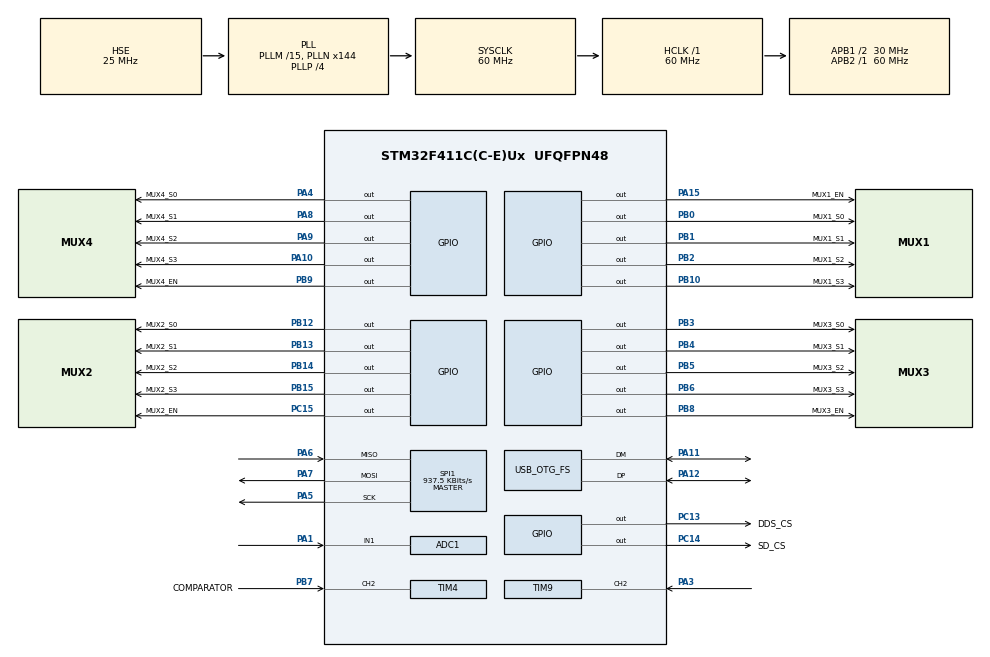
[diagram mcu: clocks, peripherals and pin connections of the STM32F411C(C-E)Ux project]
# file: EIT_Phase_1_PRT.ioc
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ADC1.Channel-2\#ChannelRegularConversion=ADC_CHANNEL_1
ADC1.ContinuousConvMode=DISABLE
ADC1.DMAContinuousRequests=ENABLE
ADC1.ExternalTrigConv=ADC_EXTERNALTRIGCONV_T2_TRGO
ADC1.NbrOfConversion=1
ADC1.NbrOfConversionFlag=1
ADC1.Rank-2\#ChannelRegularConversion=1
ADC1.SamplingTime-2\#ChannelRegularConversion=ADC_SAMPLETIME_15CYCLES
ADC1.master=1
Dma.ADC1.0.Direction=DMA_PERIPH_TO_MEMORY
Dma.ADC1.0.FIFOMode=DMA_FIFOMODE_DISABLE
Dma.ADC1.0.Instance=DMA2_Stream0
Dma.ADC1.0.MemDataAlignment=DMA_MDATAALIGN_HALFWORD
Dma.ADC1.0.MemInc=DMA_MINC_ENABLE
Dma.ADC1.0.Mode=DMA_CIRCULAR
Dma.ADC1.0.PeriphDataAlignment=DMA_PDATAALIGN_HALFWORD
Dma.ADC1.0.PeriphInc=DMA_PINC_DISABLE
Dma.ADC1.0.Priority=DMA_PRIORITY_LOW
Dma.Request0=ADC1
Mcu.Family=STM32F4
Mcu.Name=STM32F411C(C-E)Ux
Mcu.Package=UFQFPN48
NVIC.DMA2_Stream0_IRQn=true\:0\:0\:false\:false\:true\:false\:true\:true
NVIC.OTG_FS_IRQn=true\:0\:0\:false\:false\:true\:false\:true\:true
NVIC.PriorityGroup=NVIC_PRIORITYGROUP_4
NVIC.TIM4_IRQn=true\:0\:0\:false\:false\:true\:true\:true\:true
PA1.Signal=ADCx_IN1
PA10.GPIO_Label=MUX4_S3
PA10.Signal=GPIO_Output
PA11.Mode=Device_Only
PA11.Signal=USB_OTG_FS_DM
PA12.Mode=Device_Only
PA12.Signal=USB_OTG_FS_DP
PA13.Mode=Serial_Wire
PA13.Signal=SYS_JTMS-SWDIO
PA14.Mode=Serial_Wire
PA14.Signal=SYS_JTCK-SWCLK
PA15.GPIO_Label=MUX1_EN
PA15.Signal=GPIO_Output
PA3.Signal=S_TIM9_CH2
PA4.GPIO_Label=MUX4_S0
PA4.Signal=GPIO_Output
PA5.Mode=Full_Duplex_Master
PA5.Signal=SPI1_SCK
PA6.Mode=Full_Duplex_Master
PA6.Signal=SPI1_MISO
PA7.Mode=Full_Duplex_Master
PA7.Signal=SPI1_MOSI
PA8.GPIO_Label=MUX4_S1
PA8.Signal=GPIO_Output
PA9.GPIO_Label=MUX4_S2
PA9.Signal=GPIO_Output
PB0.GPIO_Label=MUX1_S0
PB0.Signal=GPIO_Output
PB1.GPIO_Label=MUX1_S1
PB1.Signal=GPIO_Output
PB10.GPIO_Label=MUX1_S3
PB10.Signal=GPIO_Output
PB12.GPIO_Label=MUX2_S0
PB12.Signal=GPIO_Output
PB13.GPIO_Label=MUX2_S1
PB13.Signal=GPIO_Output
PB14.GPIO_Label=MUX2_S2
PB14.Signal=GPIO_Output
PB15.GPIO_Label=MUX2_S3
PB15.Signal=GPIO_Output
PB2.GPIO_Label=MUX1_S2
PB2.Signal=GPIO_Output
PB3.GPIO_Label=MUX3_S0
PB3.Signal=GPIO_Output
PB4.GPIO_Label=MUX3_S1
PB4.Signal=GPIO_Output
PB5.GPIO_Label=MUX3_S2
PB5.Signal=GPIO_Output
PB6.GPIO_Label=MUX3_S3
PB6.Signal=GPIO_Output
PB7.GPIO_Label=COMPARATOR
PB7.GPIO_PuPd=GPIO_PULLDOWN
PB7.Signal=S_TIM4_CH2
PB8.GPIO_Label=MUX3_EN
PB8.Signal=GPIO_Output
PB9.GPIO_Label=MUX4_EN
PB9.Signal=GPIO_Output
PC13-ANTI_TAMP.GPIO_Label=DDS_CS
PC13-ANTI_TAMP.Signal=GPIO_Output
PC14-OSC32_IN.GPIO_Label=SD_CS
PC14-OSC32_IN.Signal=GPIO_Output
PC15-OSC32_OUT.GPIO_Label=MUX2_EN
PC15-OSC32_OUT.Signal=GPIO_Output
PH0\ -\ OSC_IN.Mode=HSE-External-Oscillator
PH0\ -\ OSC_IN.Signal=RCC_OSC_IN
PH1\ -\ OSC_OUT.Mode=HSE-External-Oscillator
PH1\ -\ OSC_OUT.Signal=RCC_OSC_OUT
ProjectManager.HeapSize=0x200
ProjectManager.StackSize=0x400
ProjectManager.TargetToolchain=STM32CubeIDE
RCC.48MHZClocksFreq_Value=48000000
RCC.AHBFreq_Value=60000000
RCC.APB1CLKDivider=RCC_HCLK_DIV2
RCC.APB1Freq_Value=30000000
RCC.APB1TimFreq_Value=60000000
RCC.APB2Freq_Value=60000000
RCC.APB2TimFreq_Value=60000000
RCC.CortexFreq_Value=60000000
RCC.HCLKFreq_Value=60000000
RCC.HSE_VALUE=25000000
RCC.HSI_VALUE=16000000
RCC.LSE_VALUE=32768
RCC.PLLM=15
RCC.PLLN=144
RCC.PLLP=RCC_PLLP_DIV4
RCC.PLLQ=5
RCC.SYSCLKFreq_VALUE=60000000
RCC.SYSCLKSource=RCC_SYSCLKSOURCE_PLLCLK
RCC.VCOOutputFreq_Value=240000000
SH.ADCx_IN1.0=ADC1_IN1,IN1
SH.S_TIM4_CH2.0=TIM4_CH2,Input_Capture2_from_TI2
SH.S_TIM9_CH2.0=TIM9_CH2,Input_Capture2_from_TI2
SPI1.BaudRatePrescaler=SPI_BAUDRATEPRESCALER_64
SPI1.CLKPolarity=SPI_POLARITY_HIGH
SPI1.CalculateBaudRate=937.5 KBits/s
SPI1.Direction=SPI_DIRECTION_2LINES
SPI1.Mode=SPI_MODE_MASTER
SPI1.VirtualType=VM_MASTER
TIM2.AutoReloadPreload=TIM_AUTORELOAD_PRELOAD_ENABLE
TIM2.Period=74
TIM2.TIM_MasterOutputTrigger=TIM_TRGO_UPDATE
TIM4.AutoReloadPreload=TIM_AUTORELOAD_PRELOAD_ENABLE
TIM4.Channel-Input_Capture2_from_TI2=TIM_CHANNEL_2
TIM4.ICFilter_CH2=1
TIM9.Channel-Input_Capture2_from_TI2=TIM_CHANNEL_2
USB_DEVICE.CLASS_NAME_FS=CDC
USB_DEVICE.VirtualMode=Cdc
USB_DEVICE.VirtualModeFS=Cdc_FS
USB_OTG_FS.VirtualMode=Device_Only
VP_TIM2_VS_ClockSourceINT.Mode=Internal
VP_TIM4_VS_ClockSourceINT.Mode=Internal
VP_USB_DEVICE_VS_USB_DEVICE_CDC_FS.Mode=CDC_FS
board=custom

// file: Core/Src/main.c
/* USER CODE BEGIN Header */
/**
  ******************************************************************************
  * @file           : main.c
  * @brief          : Main program body
  ******************************************************************************
  * @attention
  *
  * Copyright (c) 2026 STMicroelectronics.
  * All rights reserved.
  *
  * This software is licensed under terms that can be found in the LICENSE file
  * in the root directory of this software component.
  * If no LICENSE file comes with this software, it is provided AS-IS.
  *
  ******************************************************************************
  */
/* USER CODE END Header */
#include "main.h"
#include "usb_device.h"

/* USER CODE BEGIN Includes */
#include "app.hpp"
/* USER CODE END Includes */

ADC_HandleTypeDef hadc1;
DMA_HandleTypeDef hdma_adc1;

SPI_HandleTypeDef hspi1;

TIM_HandleTypeDef htim2;
TIM_HandleTypeDef htim4;
TIM_HandleTypeDef htim9;

void SystemClock_Config(void);
static void MX_GPIO_Init(void);
static void MX_DMA_Init(void);
static void MX_SPI1_Init(void);
static void MX_ADC1_Init(void);
static void MX_TIM2_Init(void);
static void MX_TIM4_Init(void);
static void MX_TIM9_Init(void);

int main(void)
{

  /* MCU Configuration--------------------------------------------------------*/

  /* Reset of all peripherals, Initializes the Flash interface and the Systick. */
  HAL_Init();

  /* Configure the system clock */
  SystemClock_Config();

  /* Initialize all configured peripherals */
  MX_GPIO_Init();
  MX_DMA_Init();
  MX_SPI1_Init();
  MX_USB_DEVICE_Init();
  MX_ADC1_Init();
  MX_TIM2_Init();
  MX_TIM4_Init();
  MX_TIM9_Init();
  /* USER CODE BEGIN 2 */
  app_setup();
  /* USER CODE END 2 */

  /* Infinite loop */
  /* USER CODE BEGIN WHILE */
  while (1)
  {
	  app_loop();
    /* USER CODE END WHILE */

  }
}

void SystemClock_Config(void)
{
  RCC_OscInitTypeDef RCC_OscInitStruct = {0};
  RCC_ClkInitTypeDef RCC_ClkInitStruct = {0};

  /** Configure the main internal regulator output voltage
  */
  __HAL_RCC_PWR_CLK_ENABLE();
  __HAL_PWR_VOLTAGESCALING_CONFIG(PWR_REGULATOR_VOLTAGE_SCALE1);

  /** Initializes the RCC Oscillators according to the specified parameters
  * in the RCC_OscInitTypeDef structure.
  */
  RCC_OscInitStruct.OscillatorType = RCC_OSCILLATORTYPE_HSE;
  RCC_OscInitStruct.HSEState = RCC_HSE_ON;
  RCC_OscInitStruct.PLL.PLLState = RCC_PLL_ON;
  RCC_OscInitStruct.PLL.PLLSource = RCC_PLLSOURCE_HSE;
  RCC_OscInitStruct.PLL.PLLM = 15;
  RCC_OscInitStruct.PLL.PLLN = 144;
  RCC_OscInitStruct.PLL.PLLP = RCC_PLLP_DIV4;
  RCC_OscInitStruct.PLL.PLLQ = 5;
  if (HAL_RCC_OscConfig(&RCC_OscInitStruct) != HAL_OK)
  {
    Error_Handler();
  }

  /** Initializes the CPU, AHB and APB buses clocks
  */
  RCC_ClkInitStruct.ClockType = RCC_CLOCKTYPE_HCLK|RCC_CLOCKTYPE_SYSCLK
                              |RCC_CLOCKTYPE_PCLK1|RCC_CLOCKTYPE_PCLK2;
  RCC_ClkInitStruct.SYSCLKSource = RCC_SYSCLKSOURCE_PLLCLK;
  RCC_ClkInitStruct.AHBCLKDivider = RCC_SYSCLK_DIV1;
  RCC_ClkInitStruct.APB1CLKDivider = RCC_HCLK_DIV2;
  RCC_ClkInitStruct.APB2CLKDivider = RCC_HCLK_DIV1;

  if (HAL_RCC_ClockConfig(&RCC_ClkInitStruct, FLASH_LATENCY_1) != HAL_OK)
  {
    Error_Handler();
  }
}

static void MX_ADC1_Init(void)
{

  ADC_ChannelConfTypeDef sConfig = {0};

  /** Configure the global features of the ADC (Clock, Resolution, Data Alignment and number of conversion)
  */
  hadc1.Instance = ADC1;
  hadc1.Init.ClockPrescaler = ADC_CLOCK_SYNC_PCLK_DIV2;
  hadc1.Init.Resolution = ADC_RESOLUTION_12B;
  hadc1.Init.ScanConvMode = DISABLE;
  hadc1.Init.ContinuousConvMode = DISABLE;
  hadc1.Init.DiscontinuousConvMode = DISABLE;
  hadc1.Init.ExternalTrigConvEdge = ADC_EXTERNALTRIGCONVEDGE_RISING;
  hadc1.Init.ExternalTrigConv = ADC_EXTERNALTRIGCONV_T2_TRGO;
  hadc1.Init.DataAlign = ADC_DATAALIGN_RIGHT;
  hadc1.Init.NbrOfConversion = 1;
  hadc1.Init.DMAContinuousRequests = ENABLE;
  hadc1.Init.EOCSelection = ADC_EOC_SINGLE_CONV;
  if (HAL_ADC_Init(&hadc1) != HAL_OK)
  {
    Error_Handler();
  }

  /** Configure for the selected ADC regular channel its corresponding rank in the sequencer and its sample time.
  */
  sConfig.Channel = ADC_CHANNEL_1;
  sConfig.Rank = 1;
  sConfig.SamplingTime = ADC_SAMPLETIME_15CYCLES;
  if (HAL_ADC_ConfigChannel(&hadc1, &sConfig) != HAL_OK)
  {
    Error_Handler();
  }

}

static void MX_SPI1_Init(void)
{

  /* SPI1 parameter configuration*/
  hspi1.Instance = SPI1;
  hspi1.Init.Mode = SPI_MODE_MASTER;
  hspi1.Init.Direction = SPI_DIRECTION_2LINES;
  hspi1.Init.DataSize = SPI_DATASIZE_8BIT;
  hspi1.Init.CLKPolarity = SPI_POLARITY_HIGH;
  hspi1.Init.CLKPhase = SPI_PHASE_1EDGE;
  hspi1.Init.NSS = SPI_NSS_SOFT;
  hspi1.Init.BaudRatePrescaler = SPI_BAUDRATEPRESCALER_64;
  hspi1.Init.FirstBit = SPI_FIRSTBIT_MSB;
  hspi1.Init.TIMode = SPI_TIMODE_DISABLE;
  hspi1.Init.CRCCalculation = SPI_CRCCALCULATION_DISABLE;
  hspi1.Init.CRCPolynomial = 10;
  if (HAL_SPI_Init(&hspi1) != HAL_OK)
  {
    Error_Handler();
  }

}

static void MX_TIM2_Init(void)
{

  TIM_ClockConfigTypeDef sClockSourceConfig = {0};
  TIM_MasterConfigTypeDef sMasterConfig = {0};

  htim2.Instance = TIM2;
  htim2.Init.Prescaler = 0;
  htim2.Init.CounterMode = TIM_COUNTERMODE_UP;
  htim2.Init.Period = 74;
  htim2.Init.ClockDivision = TIM_CLOCKDIVISION_DIV1;
  htim2.Init.AutoReloadPreload = TIM_AUTORELOAD_PRELOAD_ENABLE;
  if (HAL_TIM_Base_Init(&htim2) != HAL_OK)
  {
    Error_Handler();
  }
  sClockSourceConfig.ClockSource = TIM_CLOCKSOURCE_INTERNAL;
  if (HAL_TIM_ConfigClockSource(&htim2, &sClockSourceConfig) != HAL_OK)
  {
    Error_Handler();
  }
  sMasterConfig.MasterOutputTrigger = TIM_TRGO_UPDATE;
  sMasterConfig.MasterSlaveMode = TIM_MASTERSLAVEMODE_DISABLE;
  if (HAL_TIMEx_MasterConfigSynchronization(&htim2, &sMasterConfig) != HAL_OK)
  {
    Error_Handler();
  }

}

static void MX_TIM4_Init(void)
{

  TIM_ClockConfigTypeDef sClockSourceConfig = {0};
  TIM_MasterConfigTypeDef sMasterConfig = {0};
  TIM_IC_InitTypeDef sConfigIC = {0};

  htim4.Instance = TIM4;
  htim4.Init.Prescaler = 0;
  htim4.Init.CounterMode = TIM_COUNTERMODE_UP;
  htim4.Init.Period = 65535;
  htim4.Init.ClockDivision = TIM_CLOCKDIVISION_DIV1;
  htim4.Init.AutoReloadPreload = TIM_AUTORELOAD_PRELOAD_ENABLE;
  if (HAL_TIM_Base_Init(&htim4) != HAL_OK)
  {
    Error_Handler();
  }
  sClockSourceConfig.ClockSource = TIM_CLOCKSOURCE_INTERNAL;
  if (HAL_TIM_ConfigClockSource(&htim4, &sClockSourceConfig) != HAL_OK)
  {
    Error_Handler();
  }
  if (HAL_TIM_IC_Init(&htim4) != HAL_OK)
  {
    Error_Handler();
  }
  sMasterConfig.MasterOutputTrigger = TIM_TRGO_RESET;
  sMasterConfig.MasterSlaveMode = TIM_MASTERSLAVEMODE_DISABLE;
  if (HAL_TIMEx_MasterConfigSynchronization(&htim4, &sMasterConfig) != HAL_OK)
  {
    Error_Handler();
  }
  sConfigIC.ICPolarity = TIM_INPUTCHANNELPOLARITY_RISING;
  sConfigIC.ICSelection = TIM_ICSELECTION_DIRECTTI;
  sConfigIC.ICPrescaler = TIM_ICPSC_DIV1;
  sConfigIC.ICFilter = 1;
  if (HAL_TIM_IC_ConfigChannel(&htim4, &sConfigIC, TIM_CHANNEL_2) != HAL_OK)
  {
    Error_Handler();
  }

}

static void MX_TIM9_Init(void)
{

  TIM_IC_InitTypeDef sConfigIC = {0};

  htim9.Instance = TIM9;
  htim9.Init.Prescaler = 0;
  htim9.Init.CounterMode = TIM_COUNTERMODE_UP;
  htim9.Init.Period = 65535;
  htim9.Init.ClockDivision = TIM_CLOCKDIVISION_DIV1;
  htim9.Init.AutoReloadPreload = TIM_AUTORELOAD_PRELOAD_DISABLE;
  if (HAL_TIM_IC_Init(&htim9) != HAL_OK)
  {
    Error_Handler();
  }
  sConfigIC.ICPolarity = TIM_INPUTCHANNELPOLARITY_RISING;
  sConfigIC.ICSelection = TIM_ICSELECTION_DIRECTTI;
  sConfigIC.ICPrescaler = TIM_ICPSC_DIV1;
  sConfigIC.ICFilter = 0;
  if (HAL_TIM_IC_ConfigChannel(&htim9, &sConfigIC, TIM_CHANNEL_2) != HAL_OK)
  {
    Error_Handler();
  }

}

static void MX_DMA_Init(void)
{

  /* DMA controller clock enable */
  __HAL_RCC_DMA2_CLK_ENABLE();

  /* DMA interrupt init */
  /* DMA2_Stream0_IRQn interrupt configuration */
  HAL_NVIC_SetPriority(DMA2_Stream0_IRQn, 0, 0);
  HAL_NVIC_EnableIRQ(DMA2_Stream0_IRQn);

}

static void MX_GPIO_Init(void)
{
  GPIO_InitTypeDef GPIO_InitStruct = {0};

  /* GPIO Ports Clock Enable */
  __HAL_RCC_GPIOC_CLK_ENABLE();
  __HAL_RCC_GPIOH_CLK_ENABLE();
  __HAL_RCC_GPIOA_CLK_ENABLE();
  __HAL_RCC_GPIOB_CLK_ENABLE();

  /*Configure GPIO pin Output Level */
  HAL_GPIO_WritePin(GPIOC, DDS_CS_Pin|SD_CS_Pin|MUX2_EN_Pin, GPIO_PIN_RESET);

  /*Configure GPIO pin Output Level */
  HAL_GPIO_WritePin(GPIOA, MUX4_S0_Pin|MUX4_S1_Pin|MUX4_S2_Pin|MUX4_S3_Pin
                          |MUX1_EN_Pin, GPIO_PIN_RESET);

  /*Configure GPIO pin Output Level */
  HAL_GPIO_WritePin(GPIOB, MUX1_S0_Pin|MUX1_S1_Pin|MUX1_S2_Pin|MUX1_S3_Pin
                          |MUX2_S0_Pin|MUX2_S1_Pin|MUX2_S2_Pin|MUX2_S3_Pin
                          |MUX3_S0_Pin|MUX3_S1_Pin|MUX3_S2_Pin|MUX3_S3_Pin
                          |MUX3_EN_Pin|MUX4_EN_Pin, GPIO_PIN_RESET);

  /*Configure GPIO pins : DDS_CS_Pin SD_CS_Pin MUX2_EN_Pin */
  GPIO_InitStruct.Pin = DDS_CS_Pin|SD_CS_Pin|MUX2_EN_Pin;
  GPIO_InitStruct.Mode = GPIO_MODE_OUTPUT_PP;
  GPIO_InitStruct.Pull = GPIO_NOPULL;
  GPIO_InitStruct.Speed = GPIO_SPEED_FREQ_LOW;
  HAL_GPIO_Init(GPIOC, &GPIO_InitStruct);

  /*Configure GPIO pins : MUX4_S0_Pin MUX4_S1_Pin MUX4_S2_Pin MUX4_S3_Pin
                           MUX1_EN_Pin */
  GPIO_InitStruct.Pin = MUX4_S0_Pin|MUX4_S1_Pin|MUX4_S2_Pin|MUX4_S3_Pin
                          |MUX1_EN_Pin;
  GPIO_InitStruct.Mode = GPIO_MODE_OUTPUT_PP;
  GPIO_InitStruct.Pull = GPIO_NOPULL;
  GPIO_InitStruct.Speed = GPIO_SPEED_FREQ_LOW;
  HAL_GPIO_Init(GPIOA, &GPIO_InitStruct);

  /*Configure GPIO pins : MUX1_S0_Pin MUX1_S1_Pin MUX1_S2_Pin MUX1_S3_Pin
                           MUX2_S0_Pin MUX2_S1_Pin MUX2_S2_Pin MUX2_S3_Pin
                           MUX3_S0_Pin MUX3_S1_Pin MUX3_S2_Pin MUX3_S3_Pin
                           MUX3_EN_Pin MUX4_EN_Pin */
  GPIO_InitStruct.Pin = MUX1_S0_Pin|MUX1_S1_Pin|MUX1_S2_Pin|MUX1_S3_Pin
                          |MUX2_S0_Pin|MUX2_S1_Pin|MUX2_S2_Pin|MUX2_S3_Pin
                          |MUX3_S0_Pin|MUX3_S1_Pin|MUX3_S2_Pin|MUX3_S3_Pin
                          |MUX3_EN_Pin|MUX4_EN_Pin;
  GPIO_InitStruct.Mode = GPIO_MODE_OUTPUT_PP;
  GPIO_InitStruct.Pull = GPIO_NOPULL;
  GPIO_InitStruct.Speed = GPIO_SPEED_FREQ_LOW;
  HAL_GPIO_Init(GPIOB, &GPIO_InitStruct);

}

void Error_Handler(void)
{
  __disable_irq();
  while (1)
  {
  }
}
